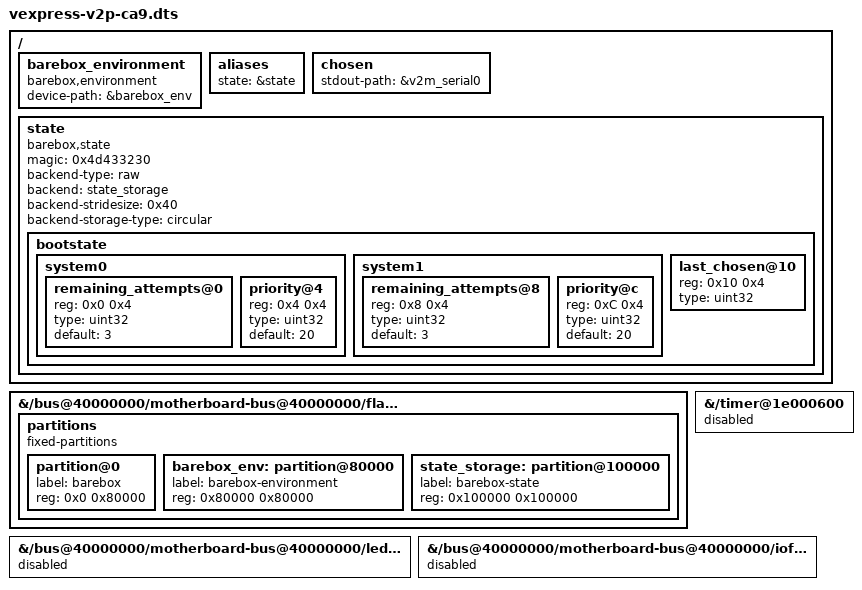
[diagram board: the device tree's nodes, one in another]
#include <arm/vexpress-v2p-ca9.dts>

/ {
	barebox_environment {
		compatible = "barebox,environment";
		device-path = &barebox_env;
	};

	aliases {
		state = &state;
	};

	chosen {
		stdout-path = &v2m_serial0;
	};

	/* State: mutable part */
	state: state {
		magic = <0x4d433230>;
		compatible = "barebox,state";
		backend-type = "raw";
		backend = <&state_storage>;
		backend-stridesize = <0x40>;
		backend-storage-type = "circular";
		#address-cells = <1>;
		#size-cells = <1>;

		bootstate {
			#address-cells = <1>;
			#size-cells = <1>;

			system0 { /* the node's name here must match the subnode's name in the 'bootstate' node */
				#address-cells = <1>;
				#size-cells = <1>;

				remaining_attempts@0 {
					reg = <0x0 0x4>;
					type = "uint32";
					default = <3>;
				};
				priority@4 {
					reg = <0x4 0x4>;
					type = "uint32";
					default = <20>;
				};
			};

			system1 { /* the node's name here must match the subnode's name in the 'bootstate' node */
				#address-cells = <1>;
				#size-cells = <1>;

				remaining_attempts@8 {
					reg = <0x8 0x4>;
					type = "uint32";
					default = <3>;
				};
				priority@c {
					reg = <0xC 0x4>;
					type = "uint32";
					default = <20>;
				};
			};

			last_chosen@10 {
				reg = <0x10 0x4>;
				type = "uint32";
			};
		};
	};
};

&{/bus@40000000/motherboard-bus@40000000/flash@0,00000000} {
	partitions {
		compatible = "fixed-partitions";
		#address-cells = <1>;
		#size-cells = <1>;

		partition@0 {
			label = "barebox";
			reg = <0x0 0x80000>;
		};

		barebox_env: partition@80000 {
			label = "barebox-environment";
			reg = <0x80000 0x80000>;
		};

		state_storage: partition@100000 {
			label = "barebox-state";
			reg = <0x100000 0x100000>;
		};
	};
};

&{/timer@1e000600} {
	status = "disabled";
};

&{/bus@40000000/motherboard-bus@40000000/leds/} {
	status = "disabled";
};

&{/bus@40000000/motherboard-bus@40000000/iofpga@7,00000000/compact-flash@1a000/} {
	status = "disabled";
};
